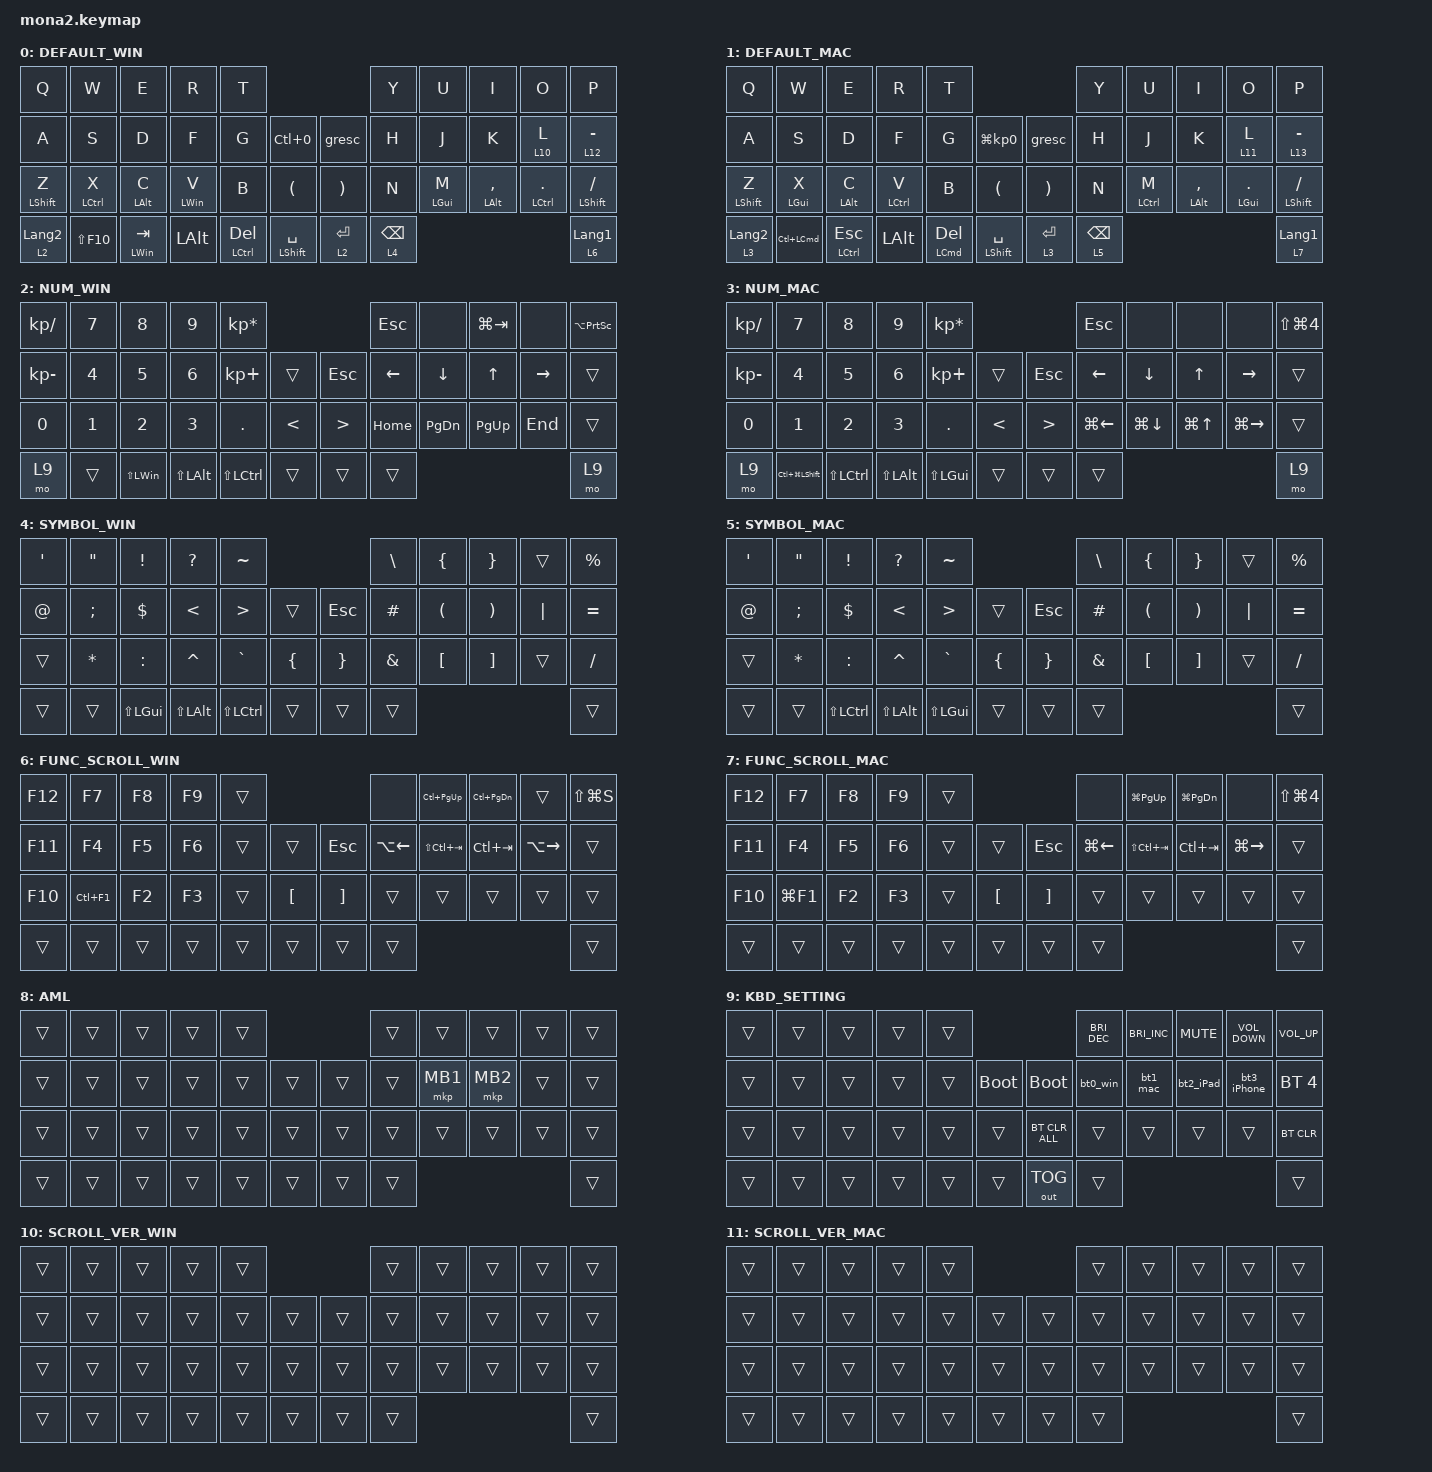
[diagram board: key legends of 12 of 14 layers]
#include <input/processors.dtsi>
#include <dt-bindings/zmk/input_transform.h>
#include <zephyr/dt-bindings/input/input-event-codes.h>
#include <behaviors.dtsi>
#include <dt-bindings/zmk/bt.h>
#include <dt-bindings/zmk/keys.h>
#include <dt-bindings/zmk/pointing.h>
#include <dt-bindings/zmk/outputs.h>

#ifndef ZMK_POINTING_DEFAULT_SCRL_VAL
#define ZMK_POINTING_DEFAULT_SCRL_VAL 70
#endif

// レイヤーの設定
#define DEFAULT_WIN 0
#define DEFAULT_MAC 1
#define NUM_WIN 2
#define NUM_MAC 3
#define SYMBOL_WIN 4
#define SYMBOL_MAC 5
#define FUNC_SCROLL_WIN 6
#define FUNC_SCROLL_MAC 7
#define AML 8
#define KBD_SETTING 9
#define SCROLL_VER_WIN 10
#define SCROLL_VER_MAC 11
#define SCROLL_HOR_WIN 12
#define SCROLL_HOR_MAC 13

/ {
    /omit-if-no-ref/
    // AML設定
    zip_temp_layer: zip_temp_layer {
        compatible = "zmk,input-processor-temp-layer";
        #input-processor-cells = <2>;

        // 以下で指定したキー以外を押すとAML解除

        excluded-positions = <
            18 // J
            19 // K
            20 // L
            32 // Ctrl/Command + .
            33 // Shift + /
            38 // Ctrl/Command + Del
            39 // Shift + Space
        >;

        // キー入力から300ms間はAMLを発動しない

        require-prior-idle-ms = <300>;
    };
};

// **************************************************
// トラボ設定
// **************************************************
&trackball_central_listener {
    status = "okay";
    device = <&trackball_central>;

    // ==========================================
    // AML設定
    // ==========================================
    // input-processors = <&zip_temp_layer AML 30000>;
    //
    //
    // ==========================================
    // スクロール設定
    // ==========================================
    // 自由スクロール
    // Mac

    scroller_mac {
        layers = <FUNC_SCROLL_MAC>;
        input-processors =
            <&zip_xy_scaler 1 6>,
            <&zip_xy_to_scroll_mapper>;
    };

    // 自由スクロール
    // Windows

    scroller_win {
        layers = <FUNC_SCROLL_WIN>;
        input-processors =
            <&zip_xy_scaler 1 4>,
            <&zip_xy_transform INPUT_TRANSFORM_X_INVERT>,
            <&zip_xy_transform INPUT_TRANSFORM_Y_INVERT>,
            <&zip_xy_to_scroll_mapper>;
    };

    // 縦横別のスクロール
    // Mac - 縦スクロール

    scroller_mac_vertical {
        layers = <SCROLL_VER_MAC>;
        input-processors =
            <&zip_y_scaler 1 6>,
            <&zip_x_scaler 0 1>,
            <&zip_xy_to_scroll_mapper>;
    };

    // 縦横別のスクロール
    // Mac - 横スクロール

    scroller_mac_horizontal {
        layers = <SCROLL_HOR_MAC>;
        input-processors =
            <&zip_x_scaler 1 6>,
            <&zip_y_scaler 0 1>,
            <&zip_xy_to_scroll_mapper>;
    };

    // 縦横別のスクロール
    // Windows - 縦スクロール

    scroller_win_vertical {
        layers = <SCROLL_VER_WIN>;
        input-processors =
            <&zip_y_scaler 1 4>,
            <&zip_x_scaler 0 1>,
            <&zip_xy_transform INPUT_TRANSFORM_Y_INVERT>,
            <&zip_xy_to_scroll_mapper>;
    };

    // 縦横別のスクロール
    // Windows - 横スクロール

    scroller_win_horizontal {
        layers = <SCROLL_HOR_WIN>;
        input-processors =
            <&zip_x_scaler 1 4>,
            <&zip_y_scaler 0 1>,
            <&zip_xy_transform INPUT_TRANSFORM_X_INVERT>,
            <&zip_xy_to_scroll_mapper>;
    };
};

// **************************************************
// マウスカーソルの挙動設定
// **************************************************

&mmv {
    delay-ms = <0>;
    time-to-max-speed-ms = <300>;
    acceleration-exponent = <1>;
};

// **************************************************
// マウススクロールの挙動設定
// **************************************************

&msc {
    delay-ms = <0>;
    time-to-max-speed-ms = <500>;
    acceleration-exponent = <1>;
};

// **************************************************
// Input-ProcessorによるAMK設定
// クリック後、250ms後にAMK解除
// **************************************************
&mkp_input_listener { input-processors = <&zip_temp_layer AML 250>; };


&mt {
    flavor = "balanced";
    tapping-term-ms = <180>;
    quick-tap-ms = <180>;
};

&lt {
    flavor = "balanced";
    tapping-term-ms = <180>;
    quick-tap-ms = <180>;
};

&sl { release-after-ms = <30000>; };

/ {
    combos {
        compatible = "zmk,combos";

        tab {
            bindings = <&kp TAB>;
            key-positions = <11 12>;
        };

        shift_tab {
            bindings = <&kp LS(TAB)>;
            key-positions = <12 13>;
        };

        Esc {
            bindings = <&kp ESCAPE>;
            key-positions = <0 1>;
        };

        left_click {
            bindings = <&mkp MB1>;
            key-positions = <18 19>;
        };

        backspace {
            bindings = <&kp BACKSPACE>;
            key-positions = <8 9>;
        };

        Globe {
            bindings = <&kp LG(SPACE)>;
            key-positions = <34 42>;
        };

        right_click {
            bindings = <&mkp MB2>;
            key-positions = <19 20>;
        };

        middle_click {
            bindings = <&mkp MB3>;
            key-positions = <18 20>;
        };

        equal {
            bindings = <&kp EQUAL>;
            key-positions = <20 21>;
        };
    };

    macros {
        to_layer_0: to_layer_0 {
            compatible = "zmk,behavior-macro-one-param";
            #binding-cells = <1>;
            bindings = <&to 0 &macro_param_1to1 &kp MACRO_PLACEHOLDER>;
            label = "TO_LAYER_0";
        };

        bt0_win: bt0 {
            compatible = "zmk,behavior-macro";
            #binding-cells = <0>;
            bindings =
                <&tog_off 1>,
                <&macro_wait_time 200>,
                <&bt BT_SEL 0 &bt BT_DISC 1 &bt BT_DISC 2 &bt BT_DISC 3 &bt BT_DISC 4>;

            label = "BT0";
        };

        bt1_mac: bt1 {
            compatible = "zmk,behavior-macro";
            #binding-cells = <0>;
            bindings =
                <&tog_off 1>,
                <&macro_wait_time 200>,
                <&bt BT_SEL 1 &bt BT_DISC 0 &bt BT_DISC 2 &bt BT_DISC 3 &bt BT_DISC 4>,
                <&macro_wait_time 500>,
                <&tog_on 1>;

            label = "BT1";
        };

        bt2_iPad: bt2_iPad {
            compatible = "zmk,behavior-macro";
            #binding-cells = <0>;
            bindings =
                <&tog_off 1>,
                <&macro_wait_time 200>,
                <&bt BT_SEL 2 &bt BT_DISC 0 &bt BT_DISC 1 &bt BT_DISC 3 &bt BT_DISC 4>,
                <&macro_wait_time 500>,
                <&tog_on 1>;

            label = "BT2_IPAD";
        };

        bt3_iPhone: bt3_iPhone {
            compatible = "zmk,behavior-macro";
            #binding-cells = <0>;
            bindings =
                <&tog_off 1>,
                <&macro_wait_time 200>,
                <&bt BT_SEL 3 &bt BT_DISC 0 &bt BT_DISC 1 &bt BT_DISC 2 &bt BT_DISC 4>,
                <&macro_wait_time 500>,
                <&tog_on 1>;

            label = "BT3_IPHONE";
        };

        // AML起動中にスクロールレイヤに入るためのマクロ(zaruSaruさん実装)

        to_scroll_layer_win: to_scroll_layer_win {
            compatible = "zmk,behavior-macro";
            #binding-cells = <0>;
            bindings =
                <&to FUNC_SCROLL_WIN>,
                <&macro_press>,
                <&mo FUNC_SCROLL_WIN>,
                <&macro_pause_for_release>,
                <&macro_release>,
                <&mo FUNC_SCROLL_WIN>;

            label = "TO_SCROLL_LAYER_WIN";
        };

        to_scroll_layer_mac: to_scroll_layer_mac {
            compatible = "zmk,behavior-macro";
            #binding-cells = <0>;
            bindings =
                <&to FUNC_SCROLL_MAC>,
                <&macro_press>,
                <&mo FUNC_SCROLL_MAC>,
                <&macro_pause_for_release>,
                <&macro_release>,
                <&mo FUNC_SCROLL_MAC>;

            label = "TO_SCROLL_LAYER_MAC";
        };

        // タップ時のみAML解除するための設定

        exit_AML: exit_AML {
            compatible = "zmk,behavior-macro";
            wait-ms = <0>;
            tap-ms = <0>;
            #binding-cells = <0>;
            bindings = <&tog_off AML>;
            label = "exit_AML";
        };

        kp_exit_AML: kp_exit_AML {
            compatible = "zmk,behavior-macro-one-param";
            wait-ms = <0>;
            tap-ms = <0>;
            #binding-cells = <1>;
            bindings = <&macro_param_1to1 &kp MACRO_PLACEHOLDER &exit_AML>;
            label = "KP_exit_AML";
        };
    };

    behaviors {
        lt_to_layer_0: lt_to_layer_0 {
            compatible = "zmk,behavior-hold-tap";
            label = "LAYER_TAP_TO_0";
            bindings = <&mo>, <&to_layer_0>;

            #binding-cells = <2>;
            tapping-term-ms = <200>;
        };

        // タップ時のみAML解除するための設定

        mt_exit_AML_on_tap: mt_exit_AML_on_tap {
            compatible = "zmk,behavior-hold-tap";
            label = "MT_exit_AML_ON_TAP";
            bindings = <&kp>, <&kp_exit_AML>;

            #binding-cells = <2>;
            tapping-term-ms = <200>;
            flavor = "tap-preferred";
            quick-tap-ms = <100>;
        };

        // 接続先に応じてデフォルトレイヤーを変更するための動作
        // zmk studioで接続先ごとにマクロ設定する。

        tog_on: toggle_layer_on_only {
            compatible = "zmk,behavior-toggle-layer";
            #binding-cells = <1>;
            display-name = "Toggle Layer On";
            toggle-mode = "on";
        };

        tog_off: toggle_layer_off_only {
            compatible = "zmk,behavior-toggle-layer";
            #binding-cells = <1>;
            display-name = "Toggle Layer Off";
            toggle-mode = "off";
        };

        // リピート付きのSpace and Shift

        sands: space_and_shift {
            compatible = "zmk,behavior-hold-tap";
            label = "SPACE_AND_SHIFT";
            #binding-cells = <2>;
            flavor = "tap-unless-interrupted";
            tapping-term-ms = <220>;
            quick-tap-ms = <125>;
            global-quick-tap;
            bindings = <&kp>, <&kp>;
        };

        mtandkp: mt_and_kp {
            compatible = "zmk,behavior-hold-tap";
            label = "MT_AND_KP";
            #binding-cells = <2>;
            flavor = "tap-unless-interrupted";
            tapping-term-ms = <220>;
            quick-tap-ms = <125>;
            global-quick-tap;
            bindings = <&mt>, <&kp>;
        };

        ltandkp: lt_and_kp {
            compatible = "zmk,behavior-hold-tap";
            label = "LT_AND_KP";
            #binding-cells = <2>;
            flavor = "tap-unless-interrupted";
            tapping-term-ms = <220>;
            quick-tap-ms = <125>;
            global-quick-tap;
            bindings = <&lt>, <&kp>;
        };
    };

    keymap {
        compatible = "zmk,keymap";

        DEFAULT_WIN {
            bindings = <
&kp Q             &kp W        &kp E             &kp R           &kp T                                                              &kp Y            &kp U           &kp I               &kp O             &kp P
&kp A             &kp S        &kp D             &kp F           &kp G             &kp LC(N0)                &gresc                 &kp H            &kp J           &kp K               &lt 10 L          &lt 12 MINUS
&mt LEFT_SHIFT Z  &mt LCTRL X  &mt LEFT_ALT C    &mt LEFT_WIN V  &kp B             &kp LEFT_PARENTHESIS      &kp RIGHT_PARENTHESIS  &kp N            &mt LEFT_GUI M  &mt LEFT_ALT COMMA  &mt LCTRL PERIOD  &mt LEFT_SHIFT SLASH
&lt 2 LANGUAGE_2  &kp LS(F10)  &mt LEFT_WIN TAB  &kp LEFT_ALT    &mt LCTRL DELETE  &mt LEFT_SHIFT SPACE      &lt 2 ENTER            &lt 4 BACKSPACE                                                        &lt 6 LANGUAGE_1
            >;

        };

        DEFAULT_MAC {
            bindings = <
&kp Q             &kp W                 &kp E                    &kp R               &kp T                                                                                                     &kp Y            &kp U               &kp I               &kp O             &kp P
&kp A             &kp S                 &kp D                    &kp F               &kp G                                    &kp LG(KP_NUMBER_0)                       &gresc                 &kp H            &kp J               &kp K               &lt 11 L          &lt 13 MINUS
&mt LEFT_SHIFT Z  &mt LEFT_GUI X        &mt LEFT_ALT C           &mt LEFT_CONTROL V  &kp B                                    &kp LEFT_PARENTHESIS                      &kp RIGHT_PARENTHESIS  &kp N            &mt LEFT_CONTROL M  &mt LEFT_ALT COMMA  &mt LEFT_GUI DOT  &mt LEFT_SHIFT SLASH
&lt 3 LANGUAGE_2  &kp LC(LEFT_COMMAND)  &mt LEFT_CONTROL ESCAPE  &kp LEFT_ALT        &mt_exit_AML_on_tap LEFT_COMMAND DELETE  &mt_exit_AML_on_tap LEFT_SHIFT SPACE      &lt 3 ENTER            &lt 5 BACKSPACE                                                            &lt 7 LANGUAGE_1
            >;

        };

        NUM_WIN {
            bindings = <
&kp KP_DIVIDE  &kp N7  &kp N8            &kp N9            &kp KP_MULTIPLY                                            &kp ESCAPE  &none          &kp LG(TAB)  &none      &kp LA(PRINTSCREEN)
&kp KP_MINUS   &kp N4  &kp N5            &kp N6            &kp KP_PLUS           &trans             &kp ESCAPE        &kp LEFT    &kp DOWN       &kp UP       &kp RIGHT  &trans
&kp N0         &kp N1  &kp N2            &kp N3            &kp PERIOD            &kp LESS_THAN      &kp GREATER_THAN  &kp HOME    &kp PAGE_DOWN  &kp PAGE_UP  &kp END    &trans
&mo 9          &trans  &kp LS(LEFT_WIN)  &kp LS(LEFT_ALT)  &kp LS(LEFT_CONTROL)  &trans             &trans            &trans                                             &mo 9
            >;
        };

        NUM_MAC {
            bindings = <
&kp KP_DIVIDE  &kp N7                  &kp N8                &kp N9            &kp KP_MULTIPLY                                        &kp ESCAPE    &none         &none       &none          &kp LS(LG(NUMBER_4))
&kp KP_MINUS   &kp N4                  &kp N5                &kp N6            &kp KP_PLUS       &trans             &kp ESCAPE        &kp LEFT      &kp DOWN      &kp UP      &kp RIGHT      &trans
&kp N0         &kp N1                  &kp N2                &kp N3            &kp PERIOD        &kp LESS_THAN      &kp GREATER_THAN  &kp LG(LEFT)  &kp LG(DOWN)  &kp LG(UP)  &kp LG(RIGHT)  &trans
&mo 9          &kp LC(LG(LEFT_SHIFT))  &kp LS(LEFT_CONTROL)  &kp LS(LEFT_ALT)  &kp LS(LEFT_GUI)  &trans             &trans            &trans                                                 &mo 9
            >;
        };

        SYMBOL_WIN {
            bindings = <
&kp SQT      &kp DOUBLE_QUOTES  &kp EXCLAMATION   &kp QUESTION      &kp TILDE                                              &kp BACKSLASH  &kp LEFT_BRACE        &kp RIGHT_BRACE        &trans    &kp PERCENT
&kp AT_SIGN  &kp SEMICOLON      &kp DOLLAR        &kp LESS_THAN     &kp GREATER_THAN  &trans              &kp ESCAPE       &kp HASH       &kp LEFT_PARENTHESIS  &kp RIGHT_PARENTHESIS  &kp PIPE  &kp EQUAL
&trans       &kp ASTERISK       &kp COLON         &kp CARET         &kp GRAVE         &kp LEFT_BRACE      &kp RIGHT_BRACE  &kp AMPERSAND  &kp LEFT_BRACKET      &kp RIGHT_BRACKET      &trans    &kp SLASH
&trans       &trans             &kp LS(LEFT_GUI)  &kp LS(LEFT_ALT)  &kp LS(LCTRL)     &trans              &trans           &trans                                                                &trans
            >;

        };

        SYMBOL_MAC {
            bindings = <
&kp SQT      &kp DOUBLE_QUOTES  &kp EXCLAMATION  &kp QUESTION      &kp TILDE                                              &kp BACKSLASH  &kp LEFT_BRACE        &kp RIGHT_BRACE        &trans    &kp PERCENT
&kp AT_SIGN  &kp SEMICOLON      &kp DOLLAR       &kp LESS_THAN     &kp GREATER_THAN  &trans              &kp ESCAPE       &kp HASH       &kp LEFT_PARENTHESIS  &kp RIGHT_PARENTHESIS  &kp PIPE  &kp EQUAL
&trans       &kp ASTERISK       &kp COLON        &kp CARET         &kp GRAVE         &kp LEFT_BRACE      &kp RIGHT_BRACE  &kp AMPERSAND  &kp LEFT_BRACKET      &kp RIGHT_BRACKET      &trans    &kp SLASH
&trans       &trans             &kp LS(LCTRL)    &kp LS(LEFT_ALT)  &kp LS(LEFT_GUI)  &trans              &trans           &trans                                                                &trans
            >;
        };

        FUNC_SCROLL_WIN {
            bindings = <
&kp F12  &kp F7      &kp F8  &kp F9  &trans                                           &none         &kp LC(PAGE_UP)  &kp LC(PAGE_DOWN)  &trans         &kp LS(LG(S))
&kp F11  &kp F4      &kp F5  &kp F6  &trans  &trans                &kp ESCAPE         &kp LA(LEFT)  &kp LS(LC(TAB))  &kp LC(TAB)        &kp LA(RIGHT)  &trans
&kp F10  &kp LC(F1)  &kp F2  &kp F3  &trans  &kp LEFT_BRACKET      &kp RIGHT_BRACKET  &trans        &trans           &trans             &trans         &trans
&trans   &trans      &trans  &trans  &trans  &trans                &trans             &trans                                                           &trans
            >;
        };

        FUNC_SCROLL_MAC {
            bindings = <
&kp F12  &kp F7      &kp F8  &kp F9  &trans                                           &none         &kp LG(PAGE_UP)  &kp LG(PAGE_DOWN)  &none          &kp LS(LG(NUMBER_4))
&kp F11  &kp F4      &kp F5  &kp F6  &trans  &trans                &kp ESCAPE         &kp LG(LEFT)  &kp LS(LC(TAB))  &kp LC(TAB)        &kp LG(RIGHT)  &trans
&kp F10  &kp LG(F1)  &kp F2  &kp F3  &trans  &kp LEFT_BRACKET      &kp RIGHT_BRACKET  &trans        &trans           &trans             &trans         &trans
&trans   &trans      &trans  &trans  &trans  &trans                &trans             &trans                                                           &trans
            >;

        };

        AML {
            bindings = <
&trans  &trans  &trans  &trans  &trans                      &trans  &trans    &trans    &trans  &trans
&trans  &trans  &trans  &trans  &trans  &trans      &trans  &trans  &mkp MB1  &mkp MB2  &trans  &trans
&trans  &trans  &trans  &trans  &trans  &trans      &trans  &trans  &trans    &trans    &trans  &trans
&trans  &trans  &trans  &trans  &trans  &trans      &trans  &trans                              &trans
            >;
        };

        KBD_SETTING {
            bindings = <
&trans  &trans  &trans  &trans  &trans                                   &kp C_BRIGHTNESS_DEC  &kp C_BRIGHTNESS_INC  &kp K_MUTE  &kp C_VOLUME_DOWN  &kp C_VOLUME_UP
&trans  &trans  &trans  &trans  &trans  &bootloader      &bootloader     &bt0_win              &bt1_mac              &bt2_iPad   &bt3_iPhone        &bt BT_SEL 4
&trans  &trans  &trans  &trans  &trans  &trans           &bt BT_CLR_ALL  &trans                &trans                &trans      &trans             &bt BT_CLR
&trans  &trans  &trans  &trans  &trans  &trans           &out OUT_TOG    &trans                                                                     &trans
            >;
        };

        SCROLL_VER_WIN {
            bindings = <
&trans  &trans  &trans  &trans  &trans                      &trans  &trans  &trans  &trans  &trans
&trans  &trans  &trans  &trans  &trans  &trans      &trans  &trans  &trans  &trans  &trans  &trans
&trans  &trans  &trans  &trans  &trans  &trans      &trans  &trans  &trans  &trans  &trans  &trans
&trans  &trans  &trans  &trans  &trans  &trans      &trans  &trans                          &trans
            >;
        };

        SCROLL_VER_MAC {
            bindings = <
&trans  &trans  &trans  &trans  &trans                      &trans  &trans  &trans  &trans  &trans
&trans  &trans  &trans  &trans  &trans  &trans      &trans  &trans  &trans  &trans  &trans  &trans
&trans  &trans  &trans  &trans  &trans  &trans      &trans  &trans  &trans  &trans  &trans  &trans
&trans  &trans  &trans  &trans  &trans  &trans      &trans  &trans                          &trans
            >;
        };

        SCROLL_HOR_WIN {
            bindings = <
&trans  &trans  &trans  &trans  &trans                      &trans  &trans  &trans  &trans  &trans
&trans  &trans  &trans  &trans  &trans  &trans      &trans  &trans  &trans  &trans  &trans  &trans
&trans  &trans  &trans  &trans  &trans  &trans      &trans  &trans  &trans  &trans  &trans  &trans
&trans  &trans  &trans  &trans  &trans  &trans      &trans  &trans                          &trans
            >;
        };

        SCROLL_HOR_MAC {
            bindings = <
&trans  &trans  &trans  &trans  &trans                      &trans  &trans  &trans  &trans  &trans
&trans  &trans  &trans  &trans  &trans  &trans      &trans  &trans  &trans  &trans  &trans  &trans
&trans  &trans  &trans  &trans  &trans  &trans      &trans  &trans  &trans  &trans  &trans  &trans
&trans  &trans  &trans  &trans  &trans  &trans      &trans  &trans                          &trans
            >;
        };
    };

};
